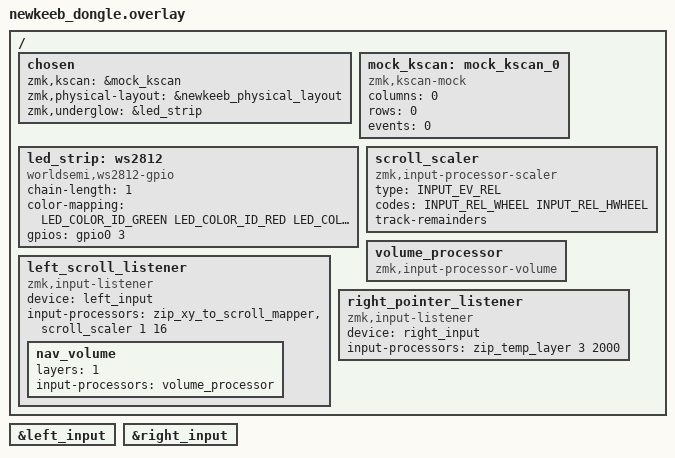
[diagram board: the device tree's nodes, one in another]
/*
 * DONGLE = split CENTRAL, keyless, USB. Runs the keymap and the trackpad
 * listeners. No matrix, no trackpad, no battery - a bare XIAO on USB.
 *
 * NOTE: acceleration now runs on the PERIPHERALS (see newkeeb_left/right.overlay)
 * where the pad's event timing is accurate. Velocity accel on the dongle got
 * garbage timing from BLE-forwarded events and did nothing. The dongle only:
 *   - LEFT:  maps the (already accelerated) motion to a wheel + scales it
 *   - RIGHT: temp-layers the (already accelerated) pointer motion
 */

#include "newkeeb-layouts.dtsi"
#include "newkeeb.dtsi"
#include <zephyr/dt-bindings/input/input-event-codes.h>
#include <input/processors.dtsi>
#include <dt-bindings/led/led.h>

/ {
    /* The central has no keys of its own -> mock kscan. */
    chosen {
        zmk,kscan = &mock_kscan;
        zmk,physical-layout = &newkeeb_physical_layout;
        zmk,underglow = &led_strip;
    };

    mock_kscan: mock_kscan_0 {
        compatible = "zmk,kscan-mock";
        columns = <0>;
        rows = <0>;
        events = <0>;
    };

    /* WS2812B RGB LED on D1 (P0.03) driven directly via GPIO bit-banging */
    led_strip: ws2812 {
        compatible = "worldsemi,ws2812-gpio";
        chain-length = <1>;
        color-mapping = <LED_COLOR_ID_GREEN LED_COLOR_ID_RED LED_COLOR_ID_BLUE>;
        gpios = <&gpio0 3 0>;
    };

    /* Scroll scaler: divides wheel deltas, keeps remainders so slow drags aren't
     * truncated. Divisor is the 2nd arg where it's used below. */
    scroll_scaler: scroll_scaler {
        compatible = "zmk,input-processor-scaler";
        #input-processor-cells = <2>;
        type = <INPUT_EV_REL>;
        codes = <INPUT_REL_WHEEL INPUT_REL_HWHEEL>;
        track-remainders;
    };

    /* Converts relative scroll wheel movement to Volume Up / Down HID consumer reports */
    volume_processor: volume_processor {
        compatible = "zmk,input-processor-volume";
        #input-processor-cells = <0>;
    };

    /* LEFT pad -> scroll.
     * Base layer: mouse scroll wheel (1 16 scaler for smoother/slower scrolling).
     * NAV layer (layer 1): volume control (up/down swipe = Vol Up / Vol Down, zero scroll leakage). */
    left_scroll_listener: left_scroll_listener {
        compatible = "zmk,input-listener";
        device = <&left_input>;
        input-processors = <&zip_xy_to_scroll_mapper &scroll_scaler 1 16>;

        nav_volume {
            layers = <1>; /* NAV layer */
            input-processors = <&volume_processor>;
        };
    };

    /* RIGHT pad -> pointer. Motion arrives already accelerated from the peripheral.
     * zip_temp_layer 3 2000 = auto-activate the MOUSE layer (index 3) while the pad
     * is in use, dropping it 2s after the last movement. */
    right_pointer_listener: right_pointer_listener {
        compatible = "zmk,input-listener";
        device = <&right_input>;
        input-processors = <&zip_temp_layer 3 2000>;
    };
};

/* Enable both receive-side proxies on the central (device-less is fine here). */
&left_input {
    status = "okay";
};

&right_input {
    status = "okay";
};
